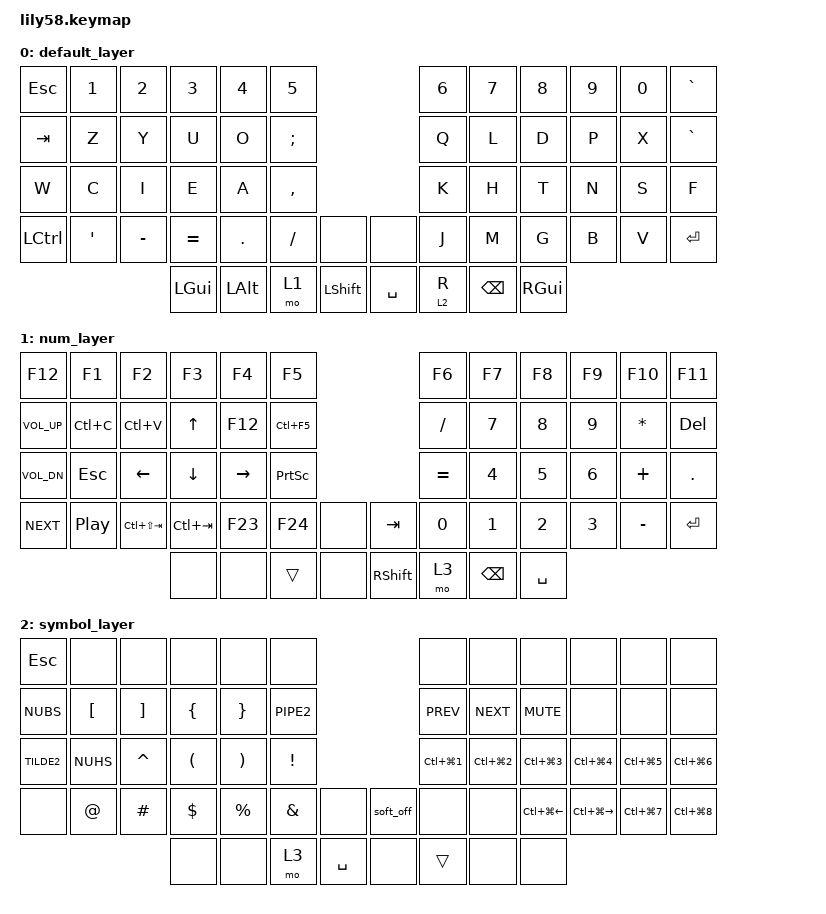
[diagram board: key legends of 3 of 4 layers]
/*
 * Copyright (c) 2020 The ZMK Contributors
 *
 * SPDX-License-Identifier: MIT
 */

#include <behaviors.dtsi>
#include <dt-bindings/zmk/keys.h>
#include <dt-bindings/zmk/bt.h>
#include <dt-bindings/zmk/pointing.h>


/ {
	keymap {
		compatible = "zmk,keymap";
        default_layer {
        // ---------------------------------------------------------------------------------------------------------------------------------
        // |  ESC  |   1   |   2   |   3   |   4   |   5   |                |   6   |   7   |   8   |   9   |   0   |   `   |
        // |  TAB  |   Z   |   Y   |   U   |   O   |   ;   |                |   Q   |   L   |   D   |   P   |   X   |   `   |
        // |   W   |   C   |   I   |   E   |   A   |   ,   |                |   K   |   H   |   T   |   N   |   S   |   F   |
        // |  CTRL |   '   |   -   |   =   |   .   |   /   |       ||       |   J   |   M   |   G   |   B   |   V   |  RET  |
        //                         |  GUI  |  ALT  |   L1  | SHIFT || SPACE |  R>L2 |  BSPC |  GUI  |
            bindings = <
            &kp ESC   &kp N1  &kp N2    &kp N3    &kp N4   &kp N5                        &kp N6  &kp N7   &kp N8   &kp N9 &kp N0 &kp GRAVE
            &kp TAB   &kp Z   &kp Y     &kp U     &kp O    &kp SEMI                      &kp Q   &kp L    &kp D    &kp P  &kp X  &kp GRAVE
            &kp W     &kp C   &kp I     &kp E     &kp A    &kp COMMA                     &kp K   &kp H    &kp T    &kp N  &kp S  &kp F
            &kp LCTRL &kp SQT &kp MINUS &kp EQUAL &kp DOT  &kp FSLH &none      &none     &kp J   &kp M    &kp G    &kp B  &kp V  &kp RET
                                        &kp LGUI  &kp LALT &mo 1    &kp LSHFT  &kp SPACE &lt 2 R &kp BSPC &kp RGUI
            >;

            sensor-bindings = <&inc_dec_kp C_VOL_UP C_VOL_DN &inc_dec_kp PG_UP PG_DN>;
        };
        num_layer {
        // ---------------------------------------------------------------------------------------------------------------------------------
        // |  F12  |   F1  |   F2  |   F3  |   F4  |   F5  |                |  F6   |   F7  |   F8  |   F9  |  F10  |  F11  |
        // | VOL_UP|  COPY | PASTE |   ^   |  F12  |  C+F5 |                |   /   |   7   |   8   |   9   |   *   |  BSPC |
        // | VOL_DN|  ESC  |   <   |   V   |   >   | PSCRN |                |   =   |   4   |   5   |   6   |   +   |   .   |
        // |  NEXT |  PLAY | tab(L)| tab(R)|  F23  |  F24  |       ||  TAB  |   0   |   1   |   2   |   3   |   -   |  RET  |
        //                         |       |       |       | SPACE || SHIFT |   L3  |  DEL  | SPACE |
            bindings = <
			&kp F12      &kp F1    &kp F2          &kp F3      &kp F4    &kp F5                      &kp F6    &kp F7   &kp F8 &kp F9 &kp F10   &kp F11
            &kp C_VOL_UP &kp LC(C) &kp LC(V)       &kp UP      &kp F12   &kp LC(F5)                  &kp FSLH  &kp N7   &kp N8 &kp N9 &kp ASTRK &kp DEL
            &kp C_VOL_DN &kp ESC   &kp LEFT        &kp DOWN    &kp RIGHT &kp PSCRN                   &kp EQUAL &kp N4   &kp N5 &kp N6 &kp PLUS  &kp DOT
            &kp C_NEXT   &kp C_PP  &kp LC(LS(TAB)) &kp LC(TAB) &kp F23   &kp F24    &none  &kp TAB   &kp N0    &kp N1   &kp N2 &kp N3 &kp MINUS &kp RET
                                                   &none       &none     &trans     &none  &kp RSHFT &mo 3     &kp BSPC &kp SPACE
            >;

            sensor-bindings = <&inc_dec_kp C_VOL_UP C_VOL_DN &inc_dec_kp PG_UP PG_DN>;
        };
        symbol_layer {
        // ---------------------------------------------------------------------------------------------------------------------------------
        // |  ESC  |       |       |       |       |       |                |       |       |       |       |       |       |
        // |   \   |   [   |   ]   |   {   |   }   |   |   |                |  NEXT |  PREV |       |       |       |       |
        // |   ~   |   #   |   ^   |   (   |   )   |   !   |                |  w(1) |  w(2) |  w(3) |  w(4) |  w(5) |  w(6) |
        // |  TODO |   "   |   £   |   $   |   %   |   &   |       ||SOFTOFF|       |       | ws(L) | ws(R) |  w(7) |  w(8) |
        //                         |       |   L3  |       | SPACE ||       |   L2  |       |       |
            bindings = <
			&kp ESC    &none    &none     &none    &none     &none                          &none          &none          &none            &none             &none          &none 
            &kp NUBS   &kp LBKT &kp RBKT  &kp LBRC &kp RBRC  &kp PIPE2                      &kp C_PREV     &kp C_NEXT     &kp C_MUTE       &none             &none          &none
            &kp TILDE2 &kp NUHS &kp CARET &kp LPAR &kp RPAR  &kp EXCL                       &kp LC(LG(N1)) &kp LC(LG(N2)) &kp LC(LG(N3))   &kp LC(LG(N4))    &kp LC(LG(N5)) &kp LC(LG(N6))
            &none      &kp AT   &kp HASH  &kp DLLR &kp PRCNT &kp AMPS  &none      &soft_off &none          &none          &kp LC(LG(LEFT)) &kp LC(LG(RIGHT)) &kp LC(LG(N7)) &kp LC(LG(N8))
                                          &none    &none     &mo 3     &kp SPACE  &none     &trans         &none          &none
            >;

            sensor-bindings = <&inc_dec_kp C_VOL_UP C_VOL_DN &inc_dec_kp PG_UP PG_DN>;
        };
        mouse_layer {
        // ---------------------------------------------------------------------------------------------------------------------------------
        // |       |       |       |       |       |       |                |       |       |       |       |       |       |
        // | BT(0) | BT(1) | BT(2) |       |       |       |                |       |       |       |       |       |       |
        // | BT_CLR|       |       |       |       |       |                |       |       |       |       |       |       |
        // |       |       |       |       |       |       |       ||       |       |       |       |       |       |       |
        //                         |       |       |   L3  |       ||       |   L3  |       |       |
            bindings = <
			&none        &none        &none          &none          &none           &none               &none          &none          &none           &none    &none   &none 
            &bt BT_SEL 0 &bt BT_SEL 1 &bt BT_SEL 2   &mmv MOVE_UP   &none           &none               &msc SCRL_UP   &msc SCRL_LEFT &msc SCRL_RIGHT &none    &none   &none 
            &bt BT_CLR   &none        &mmv MOVE_LEFT &mmv MOVE_DOWN &mmv MOVE_RIGHT &none               &msc SCRL_DOWN &mkp MB1       &mkp MB3        &mkp MB2 &none   &none 
            &kp F12      &kp F1       &kp F2         &kp F3         &kp F4          &kp F5              &kp F6         &kp F7         &kp F8          &kp F9   &kp F10 &kp F11
                                                     &none          &none           &trans &none  &none &trans         &none          &none 
            >;

            sensor-bindings = <&inc_dec_kp C_VOL_UP C_VOL_DN &inc_dec_kp PG_UP PG_DN>;
        };
	};
};
